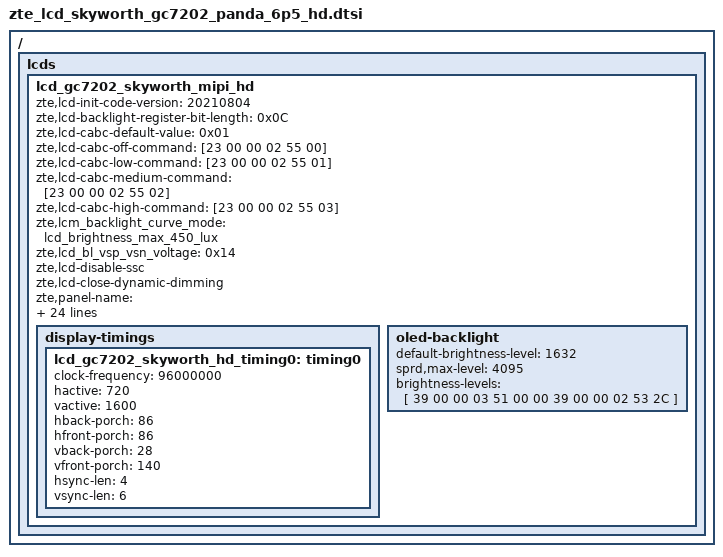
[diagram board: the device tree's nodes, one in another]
/ { lcds {
	lcd_gc7202_skyworth_mipi_hd: lcd_gc7202_skyworth_mipi_hd {
		zte,lcd-init-code-version = "20210804";
		zte,lcd-backlight-register-bit-length = <0x0C>;
		zte,lcd-cabc-default-value = <0x01>;
		zte,lcd-cabc-off-command = [23 00 00 02 55 00];
		zte,lcd-cabc-low-command = [23 00 00 02 55 01];
		zte,lcd-cabc-medium-command = [23 00 00 02 55 02];
		zte,lcd-cabc-high-command = [23 00 00 02 55 03];
		zte,lcm_backlight_curve_mode = "lcd_brightness_max_450_lux";
		zte,lcd_bl_vsp_vsn_voltage = <0x14>;
		zte,lcd-disable-ssc;
		zte,lcd-close-dynamic-dimming;
		zte,panel-name = "lcd_gc7202_skyworth_6p517_mipi_hd_galaxycore";
		zte,lcd-delay-open-bl-value = <34>;

		sprd,dsi-work-mode = <1>; /* video burst mode*/
		sprd,dsi-lane-number = <4>;
		sprd,dsi-color-format = "rgb888";

		sprd,phy-bit-clock = <700000>;	/* kbps */
		sprd,phy-escape-clock = <20000>;/* kHz */

		sprd,width-mm = <67932>;
		sprd,height-mm = <150960>;

		sprd,esd-check-enable = <1>;/* 0:close , 1:open */
		sprd,esd-check-mode = <1>;/* 0:REG ,1:TE  */
		sprd,esd-check-period = <1000>;
		sprd,esd-check-register = <0x0A>;
		sprd,esd-check-value = <0x9C>;

		sprd,reset-on-sequence = <1 5>, <0 10>, <1 35>;
		sprd,reset-off-sequence = <1 5>;
		sprd,initial-command = [
39 00 00 04 FF 55 AA 66
39 00 00 02 FF B3
39 00 00 02 FB 00
39 00 00 02 FF A3
39 00 00 02 FA 01
39 00 00 02 FF 27
39 00 00 11 01 A2 20 00 10 32 54 76 98 BA 00 00 00 00 00 00 00
39 00 00 11 02 00 01 02 03 04 05 06 07 08 09 0A 0B 00 00 00 00
39 00 00 11 03 40 10 08 00 00 00 00 00 00 00 88 04 00 00 00 00
39 00 00 11 04 03 25 80 55 5D 55 AD 05 00 00 1C 00 00 00 00 00
39 00 00 11 06 40 00 00 00 40 55 00 03 12 13 02 01 19 00 00 00
39 00 00 11 07 00 00 00 00 00 00 40 00 00 00 00 00 00 00 00 00
39 00 00 11 08 45 86 02 00 00 00 00 00 D0 00 80 00 00 00 00 00
39 00 00 11 09 00 00 00 00 00 00 00 00 00 00 00 00 00 00 00 00
39 00 00 11 0A 00 00 00 00 00 00 00 00 00 00 00 00 00 00 00 00
39 00 00 11 0B 00 00 00 00 00 00 00 00 00 00 00 00 00 00 00 00
39 00 00 11 0C 00 00 00 00 00 00 00 00 00 00 00 03 FF 00 26 04
39 00 00 11 0D 00 64 CB 00 33 03 00 00 00 00 00 00 00 00 00 00
39 00 00 09 10 FF 00 FF 00 FF 00 FF 00
39 00 00 11 43 CF 06 55 10 CF 02 57 10 CF 08 54 10 CF 06 55 10
39 00 00 11 44 CF 08 54 10 D1 00 58 10 CE 44 36 10 00 00 00 00
39 00 00 11 45 00 00 00 00 00 00 00 00 1E 40 55 55 07 40 55 55
39 00 00 11 46 57 40 55 55 97 46 55 55 27 00 00 00 00 00 00 00
39 00 00 11 47 27 40 17 07 00 00 00 00 27 40 17 07 00 00 00 00
39 00 00 11 48 27 40 17 07 28 08 09 00 D9 06 78 06 2B 06 55 10
39 00 00 11 49 2B 06 55 10 2B 06 55 10 2B 02 57 10 2B 08 54 10
39 00 00 11 4A 2B 06 55 10 2B 08 54 10 2D 00 58 10 2A 44 36 10
39 00 00 11 4B 00 00 00 00 00 00 00 00 00 00 00 00 00 00 00 00
39 00 00 11 4C 00 00 00 00 04 40 00 00 41 46 00 00 27 00 00 00
39 00 00 11 4D 00 00 00 00 00 00 70 06 00 00 00 00 00 00 70 06
39 00 00 11 4E 00 00 00 00 00 00 70 06 28 08 09 01 11 00 58 01
39 00 00 11 4F 2B 06 55 10 2B 06 55 10 2B 06 55 10 2B 02 57 10
39 00 00 11 50 2B 08 54 10 2B 06 55 10 2B 08 54 10 2D 00 58 10
39 00 00 11 51 2A 44 36 10 00 00 00 00 00 00 00 00 00 00 00 00
39 00 00 11 52 00 00 00 00 00 00 00 00 04 00 01 00 41 06 01 00
39 00 00 11 53 27 00 00 00 00 00 00 00 00 00 70 06 00 00 00 00
39 00 00 11 54 00 00 70 06 00 00 00 00 00 00 70 06 28 08 09 02
39 00 00 11 55 11 00 58 01 2B 06 55 10 2B 06 55 10 2B 06 55 10
39 00 00 11 56 2B 02 57 10 2B 08 54 10 2B 06 55 10 2B 08 54 10
39 00 00 11 57 2D 00 58 10 2A 44 36 10 00 00 00 00 00 00 00 00
39 00 00 11 58 00 00 00 00 00 00 00 00 00 00 00 00 04 00 04 00
39 00 00 11 59 41 06 04 00 27 00 00 00 00 00 00 00 00 00 70 06
39 00 00 11 5A 00 00 00 00 00 00 70 06 00 00 00 00 00 00 70 06
39 00 00 11 5B 28 08 09 03 11 00 58 01 2B 06 55 10 2B 06 55 10
39 00 00 11 5C 2B 06 55 10 2B 02 57 10 2B 08 54 10 2B 06 55 10
39 00 00 11 5D 2B 08 54 10 2D 00 58 10 2A 44 36 10 00 00 00 00
39 00 00 11 5E 00 00 00 00 00 00 00 00 00 00 00 00 00 00 00 00
39 00 00 11 5F 04 00 10 00 41 06 10 00 27 00 00 00 00 00 00 00
39 00 00 11 60 00 00 70 06 00 00 00 00 00 00 70 06 00 00 00 00
39 00 00 11 61 00 00 70 06 28 08 09 04 11 00 58 01 2B 06 55 10
39 00 00 11 62 2B 06 55 10 2B 06 55 10 2B 02 57 10 2B 08 54 10
39 00 00 11 63 2B 06 55 10 2B 08 54 10 2D 00 58 10 2A 44 36 10
39 00 00 11 64 00 00 00 00 00 00 00 00 00 00 00 00 00 00 00 00
39 00 00 11 65 00 00 00 00 04 00 40 00 41 06 40 00 27 00 00 00
39 00 00 11 66 00 00 00 00 00 00 70 06 00 00 00 00 00 00 70 06
39 00 00 11 67 00 00 00 00 00 00 70 06 28 08 09 05 11 00 58 01
39 00 00 11 68 2B 06 55 10 2B 06 55 10 2B 06 55 10 2B 02 57 10
39 00 00 11 69 2B 08 54 10 2B 06 55 10 2B 08 54 10 2D 00 58 10
39 00 00 11 6A 2A 44 36 10 00 00 00 00 00 00 00 00 00 00 00 00
39 00 00 11 6B 00 00 00 00 00 00 00 00 04 00 00 01 41 06 00 01
39 00 00 11 6C 27 00 00 00 00 00 00 00 00 00 70 06 00 00 00 00
39 00 00 11 6D 00 00 70 06 00 00 00 00 00 00 70 06 28 08 09 06
39 00 00 11 6E 11 00 58 01 2B 06 55 10 2B 06 55 10 2B 06 55 10
39 00 00 11 6F 2B 02 57 10 2B 08 54 10 2B 06 55 10 2B 08 54 10
39 00 00 11 70 2D 00 58 10 2A 44 36 10 00 00 00 00 00 00 00 00
39 00 00 11 71 00 00 00 00 00 00 00 00 00 00 00 00 04 00 00 04
39 00 00 11 72 41 06 00 04 27 00 00 00 00 00 00 00 00 00 70 06
39 00 00 11 73 00 00 00 00 00 00 70 06 00 00 00 00 00 00 70 06
39 00 00 11 74 28 08 09 07 11 00 58 01 2B 06 55 10 2B 06 55 10
39 00 00 11 75 2B 06 55 10 2B 02 57 10 2B 08 54 10 2B 06 55 10
39 00 00 11 76 2B 08 54 10 2D 00 58 10 2A 44 36 10 00 00 00 00
39 00 00 11 77 00 00 00 00 00 00 00 00 00 00 00 00 00 00 00 00
39 00 00 11 78 04 00 00 10 41 06 00 10 27 00 00 00 00 00 00 00
39 00 00 11 79 00 00 70 06 00 00 00 00 00 00 70 06 00 00 00 00
39 00 00 11 7A 00 00 70 06 28 08 09 08 11 00 58 01 2B 06 55 10
39 00 00 11 7B 2B 06 55 10 2B 06 55 10 2B 02 57 10 2B 08 54 10
39 00 00 11 7C 2B 06 55 10 2B 08 54 10 2D 00 58 10 2A 44 36 10
39 00 00 11 7D 09 00 00 40 41 06 00 40 07 C0 FF FF 21 80 AA AA
39 00 00 11 7E 04 00 00 00 00 00 00 00 00 00 00 00 00 00 00 00
39 00 00 11 7F 53 86 00 00 00 00 27 00 53 86 00 00 00 00 27 00
39 00 00 11 80 53 86 00 00 00 00 27 00 28 08 09 09 11 00 58 11
39 00 00 11 81 00 00 00 00 00 00 00 00 00 00 00 00 00 00 00 00
39 00 00 11 82 00 00 00 00 00 00 00 00 00 00 00 00 00 00 00 00
39 00 00 11 83 00 00 00 00 00 00 00 00 00 00 00 00 00 00 00 00
39 00 00 11 84 00 00 00 00 00 00 00 00 00 00 00 00 00 00 00 00
39 00 00 11 85 00 00 00 00 00 00 00 00 00 00 00 00 00 00 00 00
39 00 00 11 86 00 00 00 00 00 00 00 00 00 00 00 00 00 00 00 0A
39 00 00 11 87 00 00 00 00 00 00 00 00 00 00 00 00 00 00 00 00
39 00 00 11 88 00 00 00 00 00 00 00 00 00 00 00 00 00 00 00 00
39 00 00 11 89 00 00 00 00 00 00 00 00 00 00 00 00 00 00 00 00
39 00 00 11 8A 00 00 00 00 00 00 00 00 00 00 00 00 00 00 00 00
39 00 00 11 8B 00 00 00 00 00 00 00 00 00 00 00 00 00 00 00 00
39 00 00 11 8C 00 00 00 00 00 00 00 00 00 00 00 00 00 00 00 00
39 00 00 09 8D 00 00 00 0B 00 00 F0 00
39 00 00 02 FF 22
39 00 00 02 E4 01
39 00 00 02 01 06
39 00 00 02 02 40
39 00 00 02 25 08
39 00 00 02 26 00
39 00 00 02 2E 6F
39 00 00 02 2F 00
39 00 00 02 36 09
39 00 00 02 37 00
39 00 00 02 3F 6F
39 00 00 02 40 00
39 00 00 02 FF 21
39 00 00 02 01 25
39 00 00 02 02 05
39 00 00 02 03 1A
39 00 00 02 04 25
39 00 00 02 05 25
39 00 00 02 06 01
39 00 00 02 07 0F
39 00 00 02 08 0D
39 00 00 02 09 0B
39 00 00 02 0A 09
39 00 00 02 0B 23
39 00 00 02 0C 23
39 00 00 02 0D 25
39 00 00 02 0E 25
39 00 00 02 0F 25
39 00 00 02 10 25
39 00 00 02 11 25
39 00 00 02 12 25
39 00 00 02 13 25
39 00 00 02 14 25
39 00 00 02 15 25
39 00 00 02 16 25
39 00 00 02 17 25
39 00 00 02 18 04
39 00 00 02 19 1A
39 00 00 02 1A 25
39 00 00 02 1B 25
39 00 00 02 1C 00
39 00 00 02 1D 0E
39 00 00 02 1E 0C
39 00 00 02 1F 0A
39 00 00 02 20 08
39 00 00 02 21 23
39 00 00 02 22 23
39 00 00 02 23 25
39 00 00 02 24 25
39 00 00 02 25 25
39 00 00 02 26 25
39 00 00 02 27 25
39 00 00 02 28 25
39 00 00 02 29 25
39 00 00 02 2A 25
39 00 00 02 2B 25
39 00 00 02 2E 00
39 00 00 02 88 A7
39 00 00 02 89 28
39 00 00 02 8A 33
39 00 00 02 94 A7
39 00 00 02 95 28
39 00 00 02 96 33
39 00 00 02 45 73
39 00 00 02 46 53
39 00 00 02 47 02
39 00 00 02 48 01
39 00 00 02 4C 53
39 00 00 02 4D 01
39 00 00 02 4E 02
39 00 00 02 5E 41
39 00 00 02 5F 21
39 00 00 02 60 22
39 00 00 02 64 41
39 00 00 02 65 22
39 00 00 02 66 21
39 00 00 02 7B 04
39 00 00 02 7C 04
39 00 00 02 7D 04
39 00 00 02 7E 03
39 00 00 02 7F 21
39 00 00 02 80 01
39 00 00 02 81 1A
39 00 00 02 82 50
39 00 00 02 83 04
39 00 00 02 87 00
39 00 00 02 8B 21
39 00 00 02 8C 1A
39 00 00 02 8D 01
39 00 00 02 8E 50
39 00 00 02 8F 04
39 00 00 02 93 00
39 00 00 02 76 40
39 00 00 02 77 40
39 00 00 02 7A 44
39 00 00 02 7B 44
39 00 00 02 AF 40
39 00 00 02 B0 40
39 00 00 02 C2 80
39 00 00 02 C6 14
39 00 00 02 D1 13
39 00 00 02 49 32
39 00 00 02 4A 32
39 00 00 02 4F 32
39 00 00 02 50 32
39 00 00 02 61 32
39 00 00 02 62 32
39 00 00 02 67 32
39 00 00 02 68 32
39 00 00 02 6D 32
39 00 00 02 6E 32
39 00 00 02 84 32
39 00 00 02 85 32
39 00 00 02 90 32
39 00 00 02 91 32
39 00 00 02 30 00
39 00 00 02 31 00
39 00 00 02 FF 21
39 00 00 02 DC 27
39 00 00 02 E0 80
39 00 00 02 E1 27
39 00 00 02 E2 80
39 00 00 02 FF 20
39 00 00 02 29 01
39 00 00 02 FF 20
39 00 00 02 2D 1F
39 00 00 02 FF B3
39 00 00 02 4A 00
39 00 00 02 7D 28
39 00 00 02 5B 00
39 00 00 02 48 23
39 00 00 02 7C 88
39 00 00 02 79 20
39 00 00 02 FF 22
39 00 00 02 0E 33
39 00 00 02 FF 20
39 00 00 02 02 25
39 00 00 02 03 25
39 00 00 02 04 46
39 00 00 02 05 46
39 00 00 02 0A 1B
39 00 00 02 0B 1B
39 00 00 02 0C 4B
39 00 00 02 0D 4B
39 00 00 02 77 74
39 00 00 02 78 74
39 00 00 02 1C 28
39 00 00 02 1D 28
39 00 00 02 A5 00
39 00 00 02 A6 FF
39 00 00 02 A9 00
39 00 00 02 AA FF
39 00 00 02 AD 00
39 00 00 02 AE FF
39 00 00 02 B1 00
39 00 00 02 B2 FF
39 00 00 02 C3 00
39 00 00 02 C4 5F
39 00 00 02 C5 00
39 00 00 02 C6 5F
39 00 00 02 B3 00
39 00 00 02 B4 20
39 00 00 02 B5 00
39 00 00 02 B6 DC
39 00 00 02 C7 00
39 00 00 02 C8 93
39 00 00 02 C9 00
39 00 00 02 CA 93
39 00 00 02 B7 00
39 00 00 02 B8 20
39 00 00 02 B9 01
39 00 00 02 BA 90
39 00 00 02 CB 00
39 00 00 02 CC 90
39 00 00 02 BB 00
39 00 00 02 BC 16
39 00 00 02 BD 00
39 00 00 02 BE 12
39 00 00 02 D5 0E
39 00 00 02 7E 01
39 00 00 02 83 04
39 00 00 02 84 04
39 00 00 02 85 01
39 00 00 02 86 8B
39 00 00 02 87 01
39 00 00 02 88 8B
39 00 00 02 8A 03
39 00 00 02 8B 03
39 00 00 02 18 66
39 00 00 02 15 6E
39 00 00 02 17 5A
39 00 00 02 A3 45
39 00 00 02 A7 45
39 00 00 02 4B FF
39 00 00 02 4C FF
39 00 00 02 4D FF
39 00 00 02 D3 03
39 00 00 02 24 99
39 00 00 02 FF 20
39 00 00 02 2D 1F
39 00 00 02 FF 23
39 00 00 11 01 00 00 00 1F 00 35 00 4C 00 6D 00 85 00 9A 00 AC
39 00 00 11 02 00 C0 00 F6 01 1C 01 52 01 77 01 AA 01 D5 01 D6
39 00 00 11 03 02 04 02 3E 02 66 02 9C 02 C1 02 F1 03 01 03 14
39 00 00 0d 04 03 2A 03 42 03 5F 03 87 03 CA 03 E8
39 00 00 11 05 00 00 00 1F 00 35 00 4C 00 6D 00 85 00 9A 00 AC
39 00 00 11 06 00 C0 00 F6 01 1C 01 52 01 77 01 AA 01 D5 01 D6
39 00 00 11 07 02 04 02 3E 02 66 02 9C 02 C1 02 F1 03 01 03 14
39 00 00 0d 08 03 2A 03 42 03 5F 03 87 03 CA 03 E8
39 00 00 11 09 00 00 00 1F 00 35 00 4C 00 6D 00 85 00 9A 00 AC
39 00 00 11 0A 00 C0 00 F6 01 1C 01 52 01 77 01 AA 01 D5 01 D6
39 00 00 11 0B 02 04 02 3E 02 66 02 9C 02 C1 02 F1 03 01 03 14
39 00 00 0d 0C 03 2A 03 42 03 5F 03 87 03 CA 03 E8
39 00 00 11 0D 00 00 00 1F 00 35 00 4C 00 6D 00 85 00 9A 00 AC
39 00 00 11 0E 00 C0 00 F6 01 1C 01 52 01 77 01 AA 01 D5 01 D6
39 00 00 11 0F 02 04 02 3E 02 66 02 9C 02 C1 02 F1 03 01 03 14
39 00 00 0d 10 03 2A 03 42 03 5F 03 87 03 CA 03 E8
39 00 00 11 11 00 00 00 1F 00 35 00 4C 00 6D 00 85 00 9A 00 AC
39 00 00 11 12 00 C0 00 F6 01 1C 01 52 01 77 01 AA 01 D5 01 D6
39 00 00 11 13 02 04 02 3E 02 66 02 9C 02 C1 02 F1 03 01 03 14
39 00 00 0d 14 03 2A 03 42 03 5F 03 87 03 CA 03 E8
39 00 00 11 15 00 00 00 1F 00 35 00 4C 00 6D 00 85 00 9A 00 AC
39 00 00 11 16 00 C0 00 F6 01 1C 01 52 01 77 01 AA 01 D5 01 D6
39 00 00 11 17 02 04 02 3E 02 66 02 9C 02 C1 02 F1 03 01 03 14
39 00 00 0d 18 03 2A 03 42 03 5F 03 87 03 CA 03 E8
39 00 00 02 FF 26
39 00 00 06 04 1D 0C 00 00 00
39 00 00 02 FF B3
39 00 00 02 3E 03
39 00 00 02 FF 20
39 00 00 02 25 06
39 00 00 02 FF B3
39 00 00 02 82 1A
39 00 00 02 FF 23
39 00 00 02 2D 61
39 00 00 02 2E 00
39 00 00 02 32 00
39 00 00 02 33 18
39 00 00 02 FF 10
39 00 00 03 51 00 00
39 00 00 02 53 2C
39 00 00 02 36 08
39 00 00 02 69 00
39 00 00 02 35 00
/*39 00 00 02 FF 24
39 00 00 02 7D 00
39 00 00 04 FF 66 99 55*/
39 00 00 02 FF 10
			05 78 00 01 11
			05 32 00 01 29
			];
		sprd,sleep-in-command = [
39 00 00 03 51 00 00
39 00 00 04 FF 55 AA 66
23 00 00 02 FF 20
23 00 00 02 4A 01
23 00 00 02 48 10
23 00 00 02 49 00
23 00 00 02 FF 21
23 00 00 02 D1 00
23 00 00 02 FF 10
23 32 00 02 28 00
23 78 00 02 10 00
39 00 00 04 FF 55 AA 66
23 00 00 02 FF 26
23 00 00 02 FB 00
39 00 00 06 04 A2 AA AA 0A
23 00 00 02 FF 10
23 00 00 02 FB 00
23 05 00 02 4F 01
			];
		sprd,sleep-in-gesture-command = [
39 00 00 03 51 00 00
39 00 00 04 FF 55 AA 66
23 00 00 02 FF 20
23 00 00 02 4A 01
23 00 00 02 48 10
23 00 00 02 49 00
23 00 00 02 FF 21
23 00 00 02 D1 00
23 00 00 02 FF 10
23 32 00 02 28 00
23 78 00 02 10 00
			];
		sprd,sleep-out-command = [
			05 78 00 01 11
			05 32 00 01 29
			];

		display-timings {
			lcd_gc7202_skyworth_hd_timing0: timing0 {
			clock-frequency = <96000000>;
			hactive = <720>;
			vactive = <1600>;
			hback-porch = <86>;
			hfront-porch = <86>;
			vback-porch = <28>;
			vfront-porch = <140>;
			hsync-len = <4>;
			vsync-len = <6>;
			};
		};

		oled-backlight {
			default-brightness-level = <1632>;
			sprd,max-level = <4095>;
			brightness-levels = [
				39 00 00 03 51 00 00
				39 00 00 02 53 2C
			];
		};
	};
};};

